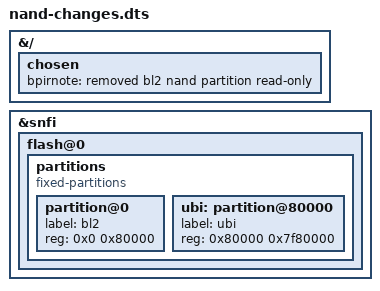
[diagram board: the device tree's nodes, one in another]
/dts-v1/;
/plugin/;

&{/} {
  chosen {
    bpirnote = "removed bl2 nand partition read-only";
  };
};

&snfi {
  flash@0 {
    /* remove from main .dtb as overlay file cannot delete a node */
    //fdtput -r /spi@1100d000/flash@0/partitions
    partitions {
      compatible = "fixed-partitions";
      #address-cells = <1>;
      #size-cells = <1>;
      partition@0 {
        label = "bl2";
        reg = <0x0 0x80000>;
      };
      ubi: partition@80000 {
        label = "ubi";
        reg = <0x80000 0x7f80000>;
      };
    };
  };
};
